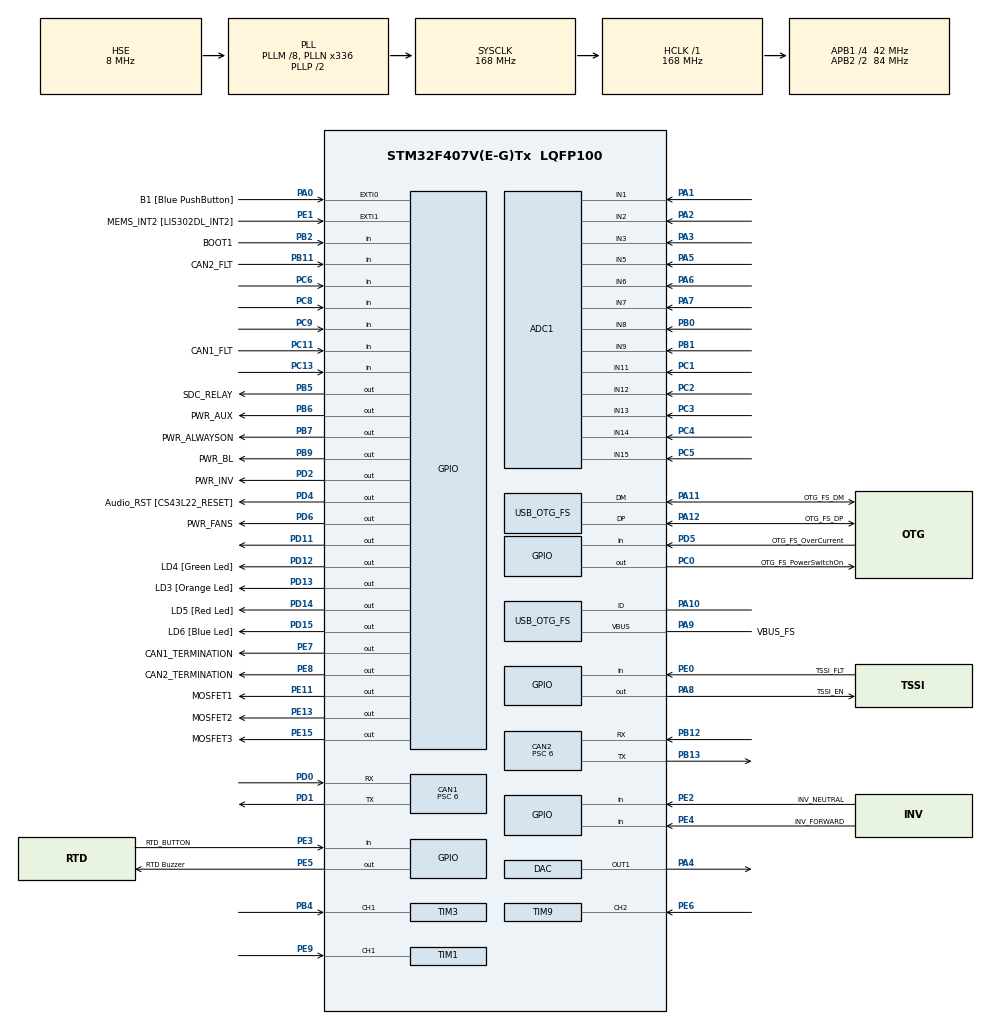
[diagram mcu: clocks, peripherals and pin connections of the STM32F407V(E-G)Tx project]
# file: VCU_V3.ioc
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ADC1.Channel-1\#ChannelRegularConversion=ADC_CHANNEL_1
ADC1.Channel-2\#ChannelRegularConversion=ADC_CHANNEL_2
ADC1.Channel-3\#ChannelRegularConversion=ADC_CHANNEL_3
ADC1.Channel-4\#ChannelRegularConversion=ADC_CHANNEL_5
ADC1.Channel-5\#ChannelRegularConversion=ADC_CHANNEL_6
ADC1.Channel-6\#ChannelRegularConversion=ADC_CHANNEL_7
ADC1.Channel-7\#ChannelRegularConversion=ADC_CHANNEL_8
ADC1.Channel-8\#ChannelRegularConversion=ADC_CHANNEL_9
ADC1.DMAContinuousRequests=ENABLE
ADC1.ExternalTrigConv=ADC_EXTERNALTRIGCONV_T2_TRGO
ADC1.NbrOfConversion=8
ADC1.NbrOfConversionFlag=1
ADC1.Rank-1\#ChannelRegularConversion=1
ADC1.Rank-2\#ChannelRegularConversion=2
ADC1.Rank-3\#ChannelRegularConversion=3
ADC1.Rank-4\#ChannelRegularConversion=4
ADC1.Rank-5\#ChannelRegularConversion=5
ADC1.Rank-6\#ChannelRegularConversion=6
ADC1.Rank-7\#ChannelRegularConversion=7
ADC1.Rank-8\#ChannelRegularConversion=8
ADC1.SamplingTime-1\#ChannelRegularConversion=ADC_SAMPLETIME_3CYCLES
ADC1.SamplingTime-2\#ChannelRegularConversion=ADC_SAMPLETIME_3CYCLES
ADC1.SamplingTime-3\#ChannelRegularConversion=ADC_SAMPLETIME_3CYCLES
ADC1.SamplingTime-4\#ChannelRegularConversion=ADC_SAMPLETIME_3CYCLES
ADC1.SamplingTime-5\#ChannelRegularConversion=ADC_SAMPLETIME_3CYCLES
ADC1.SamplingTime-6\#ChannelRegularConversion=ADC_SAMPLETIME_3CYCLES
ADC1.SamplingTime-7\#ChannelRegularConversion=ADC_SAMPLETIME_3CYCLES
ADC1.SamplingTime-8\#ChannelRegularConversion=ADC_SAMPLETIME_3CYCLES
ADC1.ScanConvMode=ENABLE
ADC1.master=1
CAN1.ABOM=ENABLE
CAN1.AWUM=ENABLE
CAN1.BS1=CAN_BS1_11TQ
CAN1.BS2=CAN_BS2_2TQ
CAN1.CalculateBaudRate=500000
CAN1.CalculateTimeBit=2000
CAN1.CalculateTimeQuantum=142.85714285714286
CAN1.Prescaler=6
CAN2.ABOM=ENABLE
CAN2.AWUM=ENABLE
CAN2.BS1=CAN_BS1_11TQ
CAN2.BS2=CAN_BS2_2TQ
CAN2.CalculateBaudRate=500000
CAN2.CalculateTimeBit=2000
CAN2.CalculateTimeQuantum=142.85714285714286
CAN2.Prescaler=6
Dma.ADC1.0.Direction=DMA_PERIPH_TO_MEMORY
Dma.ADC1.0.FIFOMode=DMA_FIFOMODE_DISABLE
Dma.ADC1.0.Instance=DMA2_Stream0
Dma.ADC1.0.MemDataAlignment=DMA_MDATAALIGN_HALFWORD
Dma.ADC1.0.MemInc=DMA_MINC_ENABLE
Dma.ADC1.0.Mode=DMA_CIRCULAR
Dma.ADC1.0.PeriphDataAlignment=DMA_PDATAALIGN_HALFWORD
Dma.ADC1.0.PeriphInc=DMA_PINC_DISABLE
Dma.ADC1.0.Priority=DMA_PRIORITY_LOW
Dma.Request0=ADC1
FREERTOS.Tasks01=defaultTask,24,128,StartDefaultTask,Default,NULL,Dynamic,NULL,NULL
FREERTOS.configENABLE_FPU=1
Mcu.Family=STM32F4
Mcu.Name=STM32F407V(E-G)Tx
Mcu.Package=LQFP100
NVIC.ADC_IRQn=true\:5\:0\:false\:false\:true\:true\:true\:true\:true
NVIC.CAN1_RX0_IRQn=true\:5\:0\:false\:false\:true\:true\:true\:true\:true
NVIC.CAN1_RX1_IRQn=true\:5\:0\:false\:false\:true\:true\:true\:true\:true
NVIC.CAN1_TX_IRQn=true\:5\:0\:false\:false\:true\:true\:true\:true\:true
NVIC.CAN2_RX0_IRQn=true\:5\:0\:false\:false\:true\:true\:true\:true\:true
NVIC.CAN2_RX1_IRQn=true\:5\:0\:false\:false\:true\:true\:true\:true\:true
NVIC.CAN2_TX_IRQn=true\:5\:0\:false\:false\:true\:true\:true\:true\:true
NVIC.DMA2_Stream0_IRQn=true\:5\:0\:false\:false\:true\:true\:false\:true\:true
NVIC.OTG_FS_IRQn=true\:5\:0\:false\:false\:true\:true\:false\:true\:true
NVIC.PriorityGroup=NVIC_PRIORITYGROUP_4
NVIC.TIM6_DAC_IRQn=true\:15\:0\:false\:false\:true\:false\:false\:true\:true
NVIC.TimeBase=TIM6_DAC_IRQn
NVIC.TimeBaseIP=TIM6
PA0-WKUP.GPIO_Label=B1 [Blue PushButton]
PA0-WKUP.GPIO_ModeDefaultEXTI=GPIO_MODE_EVT_RISING
PA0-WKUP.GPIO_PuPd=GPIO_NOPULL
PA0-WKUP.Signal=GPXTI0
PA1.Signal=ADCx_IN1
PA10.Mode=OTG/Dual_Role_Device
PA10.Signal=USB_OTG_FS_ID
PA11.GPIO_Label=OTG_FS_DM
PA11.GPIO_Mode=GPIO_MODE_AF_PP
PA11.GPIO_PuPd=GPIO_NOPULL
PA11.GPIO_Speed=GPIO_SPEED_FREQ_LOW
PA11.Mode=Device_Only
PA11.Signal=USB_OTG_FS_DM
PA12.GPIO_Label=OTG_FS_DP
PA12.GPIO_Mode=GPIO_MODE_AF_PP
PA12.GPIO_PuPd=GPIO_NOPULL
PA12.GPIO_Speed=GPIO_SPEED_FREQ_LOW
PA12.Mode=Device_Only
PA12.Signal=USB_OTG_FS_DP
PA13.GPIO_Label=SWDIO
PA13.Mode=Serial_Wire
PA13.Signal=SYS_JTMS-SWDIO
PA14.GPIO_Label=SWCLK
PA14.Mode=Serial_Wire
PA14.Signal=SYS_JTCK-SWCLK
PA2.Signal=ADCx_IN2
PA3.Signal=ADCx_IN3
PA4.Signal=COMP_DAC1_group
PA5.Signal=ADCx_IN5
PA6.Signal=ADCx_IN6
PA7.Signal=ADCx_IN7
PA8.GPIO_Label=TSSI_EN
PA8.Signal=GPIO_Output
PA9.GPIO_Label=VBUS_FS
PA9.GPIO_Mode=GPIO_MODE_INPUT
PA9.GPIO_PuPd=GPIO_NOPULL
PA9.Mode=Activate_VBUS
PA9.Signal=USB_OTG_FS_VBUS
PB0.Signal=ADCx_IN8
PB1.Signal=ADCx_IN9
PB10.GPIO_Label=CLK_IN [MP45DT02_CLK]
PB10.GPIO_Mode=GPIO_MODE_AF_PP
PB10.GPIO_PuPd=GPIO_NOPULL
PB10.GPIO_Speed=GPIO_SPEED_FREQ_LOW
PB10.Signal=I2S2_CK
PB11.GPIO_Label=CAN2_FLT
PB11.Signal=GPIO_Input
PB12.Mode=CAN_Activate
PB12.Signal=CAN2_RX
PB13.Mode=CAN_Activate
PB13.Signal=CAN2_TX
PB2.GPIO_Label=BOOT1
PB2.GPIO_Mode=GPIO_MODE_INPUT
PB2.GPIO_PuPd=GPIO_NOPULL
PB2.Signal=GPIO_Input
PB3.Signal=SYS_JTDO-SWO
PB4.Signal=S_TIM3_CH1
PB5.GPIO_Label=SDC_RELAY
PB5.Signal=GPIO_Output
PB6.GPIO_Label=PWR_AUX
PB6.Signal=GPIO_Output
PB7.GPIO_Label=PWR_ALWAYSON
PB7.Signal=GPIO_Output
PB9.GPIO_Label=PWR_BL
PB9.Signal=GPIO_Output
PC0.GPIO_Label=OTG_FS_PowerSwitchOn
PC0.GPIO_PuPd=GPIO_NOPULL
PC0.GPIO_Speed=GPIO_SPEED_FREQ_LOW
PC0.PinState=GPIO_PIN_SET
PC0.Signal=GPIO_Output
PC1.Signal=ADCx_IN11
PC11.GPIO_Label=CAN1_FLT
PC11.Signal=GPIO_Input
PC13-ANTI_TAMP.Signal=GPIO_Input
PC14-OSC32_IN.GPIO_Label=PC14-OSC32_IN
PC14-OSC32_IN.Mode=LSE-External-Oscillator
PC14-OSC32_IN.Signal=RCC_OSC32_IN
PC15-OSC32_OUT.GPIO_Label=PC15-OSC32_OUT
PC15-OSC32_OUT.Mode=LSE-External-Oscillator
PC15-OSC32_OUT.Signal=RCC_OSC32_OUT
PC2.Signal=ADCx_IN12
PC3.Signal=ADCx_IN13
PC4.Signal=ADCx_IN14
PC5.Signal=ADCx_IN15
PC6.Signal=GPIO_Input
PC7.GPIO_Label=I2S3_MCK [CS43L22_MCLK]
PC7.GPIO_Mode=GPIO_MODE_AF_PP
PC7.GPIO_PuPd=GPIO_NOPULL
PC7.GPIO_Speed=GPIO_SPEED_FREQ_LOW
PC7.Signal=I2S3_MCK
PC8.Signal=GPIO_Input
PC9.Signal=GPIO_Input
PD0.Mode=CAN_Activate
PD0.Signal=CAN1_RX
PD1.Mode=CAN_Activate
PD1.Signal=CAN1_TX
PD11.Signal=GPIO_Output
PD12.GPIO_Label=LD4 [Green Led]
PD12.GPIO_PuPd=GPIO_NOPULL
PD12.GPIO_Speed=GPIO_SPEED_FREQ_LOW
PD12.Signal=GPIO_Output
PD13.GPIO_Label=LD3 [Orange Led]
PD13.GPIO_PuPd=GPIO_NOPULL
PD13.GPIO_Speed=GPIO_SPEED_FREQ_LOW
PD13.Signal=GPIO_Output
PD14.GPIO_Label=LD5 [Red Led]
PD14.GPIO_PuPd=GPIO_NOPULL
PD14.GPIO_Speed=GPIO_SPEED_FREQ_LOW
PD14.Signal=GPIO_Output
PD15.GPIO_Label=LD6 [Blue Led]
PD15.GPIO_PuPd=GPIO_NOPULL
PD15.GPIO_Speed=GPIO_SPEED_FREQ_LOW
PD15.Signal=GPIO_Output
PD2.GPIO_Label=PWR_INV
PD2.Signal=GPIO_Output
PD4.GPIO_Label=Audio_RST [CS43L22_RESET]
PD4.GPIO_PuPd=GPIO_NOPULL
PD4.GPIO_Speed=GPIO_SPEED_FREQ_LOW
PD4.Signal=GPIO_Output
PD5.GPIO_Label=OTG_FS_OverCurrent
PD5.GPIO_Mode=GPIO_MODE_INPUT
PD5.GPIO_PuPd=GPIO_NOPULL
PD5.Signal=GPIO_Input
PD6.GPIO_Label=PWR_FANS
PD6.Signal=GPIO_Output
PE0.GPIO_Label=TSSI_FLT
PE0.Signal=GPIO_Input
PE1.GPIO_Label=MEMS_INT2 [LIS302DL_INT2]
PE1.GPIO_ModeDefaultEXTI=GPIO_MODE_EVT_RISING
PE1.GPIO_PuPd=GPIO_NOPULL
PE1.Signal=GPXTI1
PE11.GPIO_Label=MOSFET1
PE11.Signal=GPIO_Output
PE13.GPIO_Label=MOSFET2
PE13.Signal=GPIO_Output
PE15.GPIO_Label=MOSFET3
PE15.Signal=GPIO_Output
PE2.GPIO_Label=INV_NEUTRAL
PE2.Signal=GPIO_Input
PE3.GPIO_Label=RTD_BUTTON
PE3.Signal=GPIO_Input
PE4.GPIO_Label=INV_FORWARD
PE4.Signal=GPIO_Input
PE5.GPIO_Label=RTD Buzzer
PE5.Signal=GPIO_Output
PE6.Signal=S_TIM9_CH2
PE7.GPIO_Label=CAN1_TERMINATION
PE7.Signal=GPIO_Output
PE8.GPIO_Label=CAN2_TERMINATION
PE8.Signal=GPIO_Output
PE9.Signal=S_TIM1_CH1
PH0-OSC_IN.GPIO_Label=PH0-OSC_IN
PH0-OSC_IN.Mode=HSE-External-Oscillator
PH0-OSC_IN.Signal=RCC_OSC_IN
PH1-OSC_OUT.GPIO_Label=PH1-OSC_OUT
PH1-OSC_OUT.Mode=HSE-External-Oscillator
PH1-OSC_OUT.Signal=RCC_OSC_OUT
ProjectManager.HeapSize=0x200
ProjectManager.StackSize=0x400
ProjectManager.TargetToolchain=CMake
RCC.48MHZClocksFreq_Value=48000000
RCC.AHBFreq_Value=168000000
RCC.APB1CLKDivider=RCC_HCLK_DIV4
RCC.APB1Freq_Value=42000000
RCC.APB1TimFreq_Value=84000000
RCC.APB2CLKDivider=RCC_HCLK_DIV2
RCC.APB2Freq_Value=84000000
RCC.APB2TimFreq_Value=168000000
RCC.CortexFreq_Value=168000000
RCC.HCLKFreq_Value=168000000
RCC.HSE_VALUE=8000000
RCC.HSI_VALUE=16000000
RCC.PLLM=8
RCC.PLLN=336
RCC.PLLQ=7
RCC.SYSCLKFreq_VALUE=168000000
RCC.SYSCLKSource=RCC_SYSCLKSOURCE_PLLCLK
RCC.VCOOutputFreq_Value=336000000
SH.ADCx_IN1.0=ADC1_IN1,IN1
SH.ADCx_IN11.0=ADC1_IN11,IN11
SH.ADCx_IN12.0=ADC1_IN12,IN12
SH.ADCx_IN13.0=ADC1_IN13,IN13
SH.ADCx_IN14.0=ADC1_IN14,IN14
SH.ADCx_IN15.0=ADC1_IN15,IN15
SH.ADCx_IN2.0=ADC1_IN2,IN2
SH.ADCx_IN3.0=ADC1_IN3,IN3
SH.ADCx_IN5.0=ADC1_IN5,IN5
SH.ADCx_IN6.0=ADC1_IN6,IN6
SH.ADCx_IN7.0=ADC1_IN7,IN7
SH.ADCx_IN8.0=ADC1_IN8,IN8
SH.ADCx_IN9.0=ADC1_IN9,IN9
SH.COMP_DAC1_group.0=DAC_OUT1,DAC_OUT1
SH.S_TIM1_CH1.0=TIM1_CH1,PWM_Input_1
SH.S_TIM3_CH1.0=TIM3_CH1,PWM_Input_1
SH.S_TIM9_CH2.0=TIM9_CH2,PWM_Input_2
TIM2.Channel-PWM\ Generation1\ No\ Output=TIM_CHANNEL_1
TIM2.Period=500-1
TIM2.Prescaler=33600-1
TIM2.TIM_MasterOutputTrigger=TIM_TRGO_UPDATE
USB_DEVICE.CLASS_NAME_FS=CDC
USB_DEVICE.MANUFACTURER_STRING-CDC_FS=DalFSAE
USB_DEVICE.PRODUCT_STRING_CDC_FS=STM32 Virtual ComPort
USB_DEVICE.VirtualMode-CDC_FS=Cdc
USB_DEVICE.VirtualModeFS=Cdc_FS
USB_OTG_FS.VirtualMode=Device_Only
VP_FREERTOS_VS_CMSIS_V2.Mode=CMSIS_V2
VP_SYS_VS_tim6.Mode=TIM6
VP_TIM1_VS_ClockSourceINT.Mode=Internal
VP_TIM2_VS_ClockSourceINT.Mode=Internal
VP_TIM2_VS_no_output1.Mode=PWM Generation1 No Output
VP_TIM3_VS_ClockSourceINT.Mode=Internal
VP_TIM9_VS_ClockSourceINT.Mode=Internal
VP_USB_DEVICE_VS_USB_DEVICE_CDC_FS.Mode=CDC_FS
board=STM32F407G-DISC1

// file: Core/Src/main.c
/* USER CODE BEGIN Header */
/**
  ******************************************************************************
  * @file           : main.c
  * @brief          : Main program body
  ******************************************************************************
  * @attention
  *
  * Copyright (c) 2024 STMicroelectronics.
  * All rights reserved.
  *
  * This software is licensed under terms that can be found in the LICENSE file
  * in the root directory of this software component.
  * If no LICENSE file comes with this software, it is provided AS-IS.
  *
  ******************************************************************************
  */
/* USER CODE END Header */
#include "main.h"
#include "cmsis_os.h"
#include "adc.h"
#include "can.h"
#include "dac.h"
#include "dma.h"
#include "iwdg.h"
#include "tim.h"
#include "usb_device.h"
#include "gpio.h"

/* USER CODE BEGIN Includes */
#include "app.h"
#include "board_outputs.h"
#include <stdint.h>
/* USER CODE END Includes */

void SystemClock_Config(void);
void MX_FREERTOS_Init(void);

int main(void)
{

  /* MCU Configuration--------------------------------------------------------*/

  /* Reset of all peripherals, Initializes the Flash interface and the Systick. */
  HAL_Init();

  /* USER CODE BEGIN Init */
  /* No user hardware access before board init. */
  /* USER CODE END Init */

  /* Configure the system clock */
  SystemClock_Config();

  /* Initialize all configured peripherals */
  MX_GPIO_Init();
  MX_DMA_Init();
  MX_ADC1_Init();
  MX_CAN1_Init();
  MX_CAN2_Init();
  MX_TIM1_Init();
  MX_TIM2_Init();
  MX_TIM3_Init();
  MX_TIM9_Init();
  MX_DAC_Init();
  MX_IWDG_Init();
  /* USER CODE BEGIN 2 */
  uint32_t status = app_init();
  (void)status;
  /* USER CODE END 2 */

  /* Init scheduler */
  osKernelInitialize();  /* Call init function for freertos objects (in cmsis_os2.c) */
  MX_FREERTOS_Init();

  /* Start scheduler */
  osKernelStart();

  /* We should never get here as control is now taken by the scheduler */

  /* Infinite loop */
  while (1)
  {

  }
}

void SystemClock_Config(void)
{
  RCC_OscInitTypeDef RCC_OscInitStruct = {0};
  RCC_ClkInitTypeDef RCC_ClkInitStruct = {0};

  /** Configure the main internal regulator output voltage
  */
  __HAL_RCC_PWR_CLK_ENABLE();
  __HAL_PWR_VOLTAGESCALING_CONFIG(PWR_REGULATOR_VOLTAGE_SCALE1);

  /** Initializes the RCC Oscillators according to the specified parameters
  * in the RCC_OscInitTypeDef structure.
  */
  RCC_OscInitStruct.OscillatorType = RCC_OSCILLATORTYPE_LSI|RCC_OSCILLATORTYPE_HSE;
  RCC_OscInitStruct.HSEState = RCC_HSE_ON;
  RCC_OscInitStruct.LSIState = RCC_LSI_ON;
  RCC_OscInitStruct.PLL.PLLState = RCC_PLL_ON;
  RCC_OscInitStruct.PLL.PLLSource = RCC_PLLSOURCE_HSE;
  RCC_OscInitStruct.PLL.PLLM = 8;
  RCC_OscInitStruct.PLL.PLLN = 336;
  RCC_OscInitStruct.PLL.PLLP = RCC_PLLP_DIV2;
  RCC_OscInitStruct.PLL.PLLQ = 7;
  if (HAL_RCC_OscConfig(&RCC_OscInitStruct) != HAL_OK)
  {
    Error_Handler();
  }

  /** Initializes the CPU, AHB and APB buses clocks
  */
  RCC_ClkInitStruct.ClockType = RCC_CLOCKTYPE_HCLK|RCC_CLOCKTYPE_SYSCLK
                              |RCC_CLOCKTYPE_PCLK1|RCC_CLOCKTYPE_PCLK2;
  RCC_ClkInitStruct.SYSCLKSource = RCC_SYSCLKSOURCE_PLLCLK;
  RCC_ClkInitStruct.AHBCLKDivider = RCC_SYSCLK_DIV1;
  RCC_ClkInitStruct.APB1CLKDivider = RCC_HCLK_DIV4;
  RCC_ClkInitStruct.APB2CLKDivider = RCC_HCLK_DIV2;

  if (HAL_RCC_ClockConfig(&RCC_ClkInitStruct, FLASH_LATENCY_5) != HAL_OK)
  {
    Error_Handler();
  }
}

void HAL_TIM_PeriodElapsedCallback(TIM_HandleTypeDef *htim)
{
  if (htim->Instance == TIM6)
  {
    HAL_IncTick();
  }
}

void Error_Handler(void)
{
  /* USER CODE BEGIN Error_Handler_Debug */
  /* User can add his own implementation to report the HAL error return state */
  __disable_irq();
  while (1)
  {
    for (uint32_t i = 0; i < OUTPUT_COUNT; i++) {
        board_output_disable(i);
    }
    board_output_enable(OUTPUT_DEBUG_LED5);
  }
  /* USER CODE END Error_Handler_Debug */
}

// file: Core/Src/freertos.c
/* USER CODE BEGIN Header */
/**
  ******************************************************************************
  * File Name          : freertos.c
  * Description        : Code for freertos applications
  ******************************************************************************
  * @attention
  *
  * Copyright (c) 2024 STMicroelectronics.
  * All rights reserved.
  *
  * This software is licensed under terms that can be found in the LICENSE file
  * in the root directory of this software component.
  * If no LICENSE file comes with this software, it is provided AS-IS.
  *
  ******************************************************************************
  */
/* USER CODE END Header */

#include "FreeRTOS.h"
#include "task.h"
#include "main.h"
#include "cmsis_os.h"

/* USER CODE BEGIN Includes */
#include "app.h"

/* USER CODE END Includes */

/* Definitions for defaultTask */
osThreadId_t defaultTaskHandle;
const osThreadAttr_t defaultTask_attributes = {
  .name = "defaultTask",
  .stack_size = 128 * 4,
  .priority = (osPriority_t) osPriorityNormal,
};

void StartDefaultTask(void *argument);

extern void MX_USB_DEVICE_Init(void);
void MX_FREERTOS_Init(void); /* (MISRA C 2004 rule 8.1) */

void MX_FREERTOS_Init(void) {

  /* Create the thread(s) */
  /* creation of defaultTask */
  defaultTaskHandle = osThreadNew(StartDefaultTask, NULL, &defaultTask_attributes);

}

void StartDefaultTask(void *argument)
{
  /* init code for USB_DEVICE */
  MX_USB_DEVICE_Init();
  /* USER CODE BEGIN StartDefaultTask */
  (void)argument;
  app_post_boot();
  app_create_tasks();
  /* Infinite loop */
  for(;;)
  {
    osDelay(1);
  }
  /* USER CODE END StartDefaultTask */
}
